# S6E2C2xL register map
Vendor: Cypress; File version: 2.1
CPU: CM4 r0p1, little endian, MPU, FPU, 4 interrupt priority bits
Registers are 32-bit, read-write, reset 0x0 unless marked. A register's access mark holds for its fields unless they carry their own. Offsets are from the block's base; [hi:lo] are bit positions.

## USBETHERCLK — USB/Ethernet Clock
Base 0x40036000
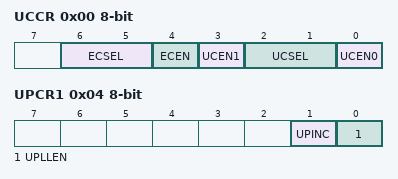
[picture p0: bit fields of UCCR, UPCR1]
0x00 UCCR 8-bit — USB/Ethernet-PLL Clock Control Register [BHW]
  [6:5] ECSEL — Ethernet clock selection bit
  [4] ECEN — Ethernet clock output enable bit
  [3] UCEN1 — USB1 clock output enable bit
  [2:1] UCSEL — USB1/0 clock selection bit
  [0] UCEN0 — USB0 clock output enable bit
0x04 UPCR1 8-bit — USB/Ethernet-PLL Control Register 1 [BHW]
  [1] UPINC — USB/Ethernet-PLL input clock selection bit
  [0] UPLLEN — USB/Ethernet-PLL oscillation enable bit
0x08 UPCR2 8-bit — USB/Ethernet-PLL Control Register 2 [BHW]
  [2:0] UPOWT — USB/Ethernet-PLL oscillation stabilization wait time setting bit
0x0C UPCR3 8-bit — USB/Ethernet-PLL Control Register 3 [BHW]
  [4:0] UPLLK — Frequency division ratio (K) setting bit of the USB/Ethernet-PLL clock
0x10 UPCR4 8-bit reset 0x3B — USB/Ethernet-PLL Control Register 4 [BHW]
  [6:0] UPLLN — Frequency division ratio (N) setting bit of the USB/Ethernet-PLL clock
0x14 UP_STR 8-bit ro — USB/Ethernet-PLL Status Register [BHW]
  [0] UPRDY — USB/Ethernet-PLL oscillation stabilization bit
0x18 UPINT_ENR 8-bit — USB/Ethernet-PLL Interrupt Source Enable Register [BHW]
  [0] UPCSE — USB/Ethernet-PLL oscillation stabilization wait complete interrupt enable bit
0x1C UPINT_CLR 8-bit wo — USB/Ethernet-PLL Interrupt Source Clear Register [BHW]
  [0] UPCSC — USB/Ethernet-PLL oscillation stabilization interrupt source clear bit
0x20 UPINT_STR 8-bit ro — USB/Ethernet-PLL Interrupt Source Status Register [BHW]
  [0] UPCSI — USB/Ethernet-PLL interrupt source status bit
0x24 UPCR5 8-bit reset 0x4 — USB/Ethernet-PLL Control Register 5 [BHW]
  [3:0] UPLLM — Frequency division ratio (M) setting bit of the USB/Ethernet-PLL clock
0x28 UPCR6 8-bit reset 0x2 — USB/Ethernet-PLL Setting Register 6 [BHW]
  [3:0] UBSR — CLKPLL division ratio setting bit
0x2C UPCR7 8-bit — USB/Ethernet-PLL Setting Register 7 [BHW]
  [0] EPLLEN — USB/Ethernet-PLL control bit in Timer mode
0x30 USBEN0 8-bit reset 0x4 — USB0 Enable Register [BHW]
  [0] USBEN0 — USB0 enable bit
0x34 USBEN1 8-bit reset 0x4 — USB1 Enable Register [BHW]
  [0] USBEN1 — USB1 enable bit

## CRC — CRC Registers
Base 0x40039000
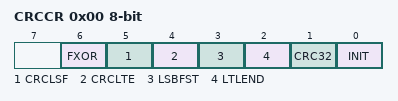
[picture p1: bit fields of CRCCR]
0x00 CRCCR 8-bit — CRC Control Register [BHW]
  [6] FXOR — Final XOR control bit
  [5] CRCLSF — CRC result bit-order setting bit
  [4] CRCLTE — CRC result byte-order setting bit
  [3] LSBFST — Bit-order setting bit
  [2] LTLEND — Byte-order setting bit
  [1] CRC32 — CRC mode selection bit
  [0] INIT — Initialization bit
0x04 CRCINIT reset 0xFFFFFFFF — Initial Value Register [BHW]
  [31:0] D — Initial value
0x08 CRCIN — Input Data Register [BHW]
  [31:0] D — Input data
0x0C CRCR ro reset 0xFFFFFFFF — CRC Register [BHW]
  [31:0] D — CRC Data

## WC — Watch Counter
Base 0x4003A000
0x00 WCRD 8-bit ro — Watch Counter Read Register [BHW]
  [5:0] CTR — Counter read bits
0x01 WCRL 8-bit — Watch Counter Reload Register [BHW]
  [5:0] RLC — Counter reload value setting bits
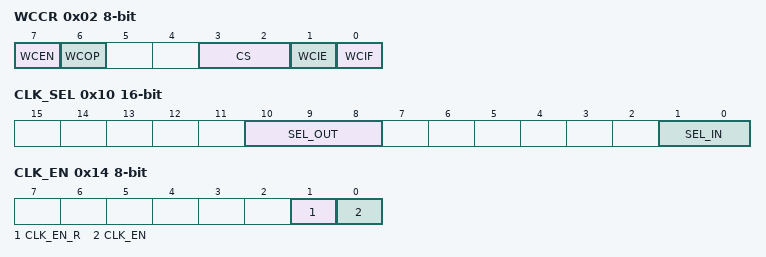
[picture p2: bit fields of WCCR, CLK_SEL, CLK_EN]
0x02 WCCR 8-bit — Watch Counter Control Register [BHW]
  [7] WCEN — Watch counter operation enable bit
  [6] WCOP ro — Watch counter operating state flag
  [3:2] CS — Count clock select bits
  [1] WCIE — Interrupt request enable bit
  [0] WCIF — Interrupt request flag bit
0x10 CLK_SEL 16-bit — Clock Selection Register [BHW]
  [10:8] SEL_OUT — Output clock selection bit
  [1:0] SEL_IN — Input clock selection bit
0x14 CLK_EN 8-bit — Division Clock Enable Register [BHW]
  [1] CLK_EN_R — Division clock enable read bit
  [0] CLK_EN — Division clock enable bit

## LSCRP — Low-speed CR Prescaler
Base 0x4003C000
0x00 LCR_PRSLD 8-bit — Low-speed CR Prescaler Control Register [BHW]
  [5:0] LCR_PRSLD — Low-speed CR Prescaler Load

## Notices in the file
Copyright (C) 2013-2016, Cypress Semiconductor Corporation or a
subsidiary of Cypress Semiconductor Corporation.  All rights reserved.
This software, including source code, documentation and related
materials ("Software"), is owned by Cypress Semiconductor Corporation or
one of its subsidiaries ("Cypress") and is protected by and subject to
worldwide patent protection (United States and foreign), United States
copyright laws and international treaty provisions. Therefore, you may use
this Software only as provided in the license agreement accompanying the
software package from which you obtained this Software ("EULA").
If no EULA applies, Cypress hereby grants you a personal, non-exclusive,
non-transferable license to copy, modify, and compile the
Software source code solely for use in connection with Cypress's
integrated circuit products.  Any reproduction, modification, translation,
compilation, or representation of this Software except as specified
above is prohibited without the express written permission of Cypress.
Disclaimer: THIS SOFTWARE IS PROVIDED AS-IS, WITH NO
WARRANTY OF ANY KIND, EXPRESS OR IMPLIED, INCLUDING,
BUT NOT LIMITED TO, NONINFRINGEMENT, IMPLIED
WARRANTIES OF MERCHANTABILITY AND FITNESS FOR A
PARTICULAR PURPOSE. Cypress reserves the right to make
changes to the Software without notice. Cypress does not assume any
liability arising out of the application or use of the Software or any
product or circuit described in the Software. Cypress does not
authorize its products for use in any products where a malfunction or
failure of the Cypress product may reasonably be expected to result in
significant property damage, injury or death ("High Risk Product"). By
including Cypress's product in a High Risk Product, the manufacturer
of such system or application assumes all risk of such use and in doing
so agrees to indemnify Cypress against all liability.
